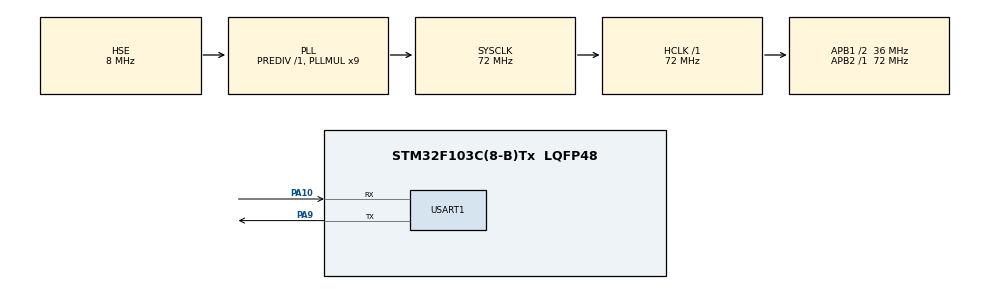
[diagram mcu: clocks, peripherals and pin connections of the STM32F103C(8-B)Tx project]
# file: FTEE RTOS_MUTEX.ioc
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FREERTOS.Mutexes01=myMutex01,Dynamic,NULL,Available
FREERTOS.Tasks01=defaultTask,24,128,StartDefaultTask,Default,NULL,Dynamic,NULL,NULL;TASK1,24,128,TASK_1,Default,NULL,Dynamic,NULL,NULL;TASK2,24,128,TASK_2,Default,NULL,Dynamic,NULL,NULL;TASK3,24,128,TASK_3,Default,NULL,Dynamic,NULL,NULL
Mcu.Family=STM32F1
Mcu.Name=STM32F103C(8-B)Tx
Mcu.Package=LQFP48
NVIC.PriorityGroup=NVIC_PRIORITYGROUP_4
NVIC.TIM1_UP_IRQn=true\:15\:0\:false\:false\:true\:false\:false\:true\:true
NVIC.TimeBase=TIM1_UP_IRQn
NVIC.TimeBaseIP=TIM1
PA10.Mode=Asynchronous
PA10.Signal=USART1_RX
PA9.Mode=Asynchronous
PA9.Signal=USART1_TX
PD0-OSC_IN.Mode=HSE-External-Oscillator
PD0-OSC_IN.Signal=RCC_OSC_IN
PD1-OSC_OUT.Mode=HSE-External-Oscillator
PD1-OSC_OUT.Signal=RCC_OSC_OUT
ProjectManager.HeapSize=0x200
ProjectManager.StackSize=0x400
ProjectManager.TargetToolchain=STM32CubeIDE
RCC.AHBFreq_Value=72000000
RCC.APB1CLKDivider=RCC_HCLK_DIV2
RCC.APB1Freq_Value=36000000
RCC.APB1TimFreq_Value=72000000
RCC.APB2Freq_Value=72000000
RCC.APB2TimFreq_Value=72000000
RCC.HCLKFreq_Value=72000000
RCC.PLLMUL=RCC_PLL_MUL9
RCC.PLLSourceVirtual=RCC_PLLSOURCE_HSE
RCC.SYSCLKFreq_VALUE=72000000
RCC.SYSCLKSource=RCC_SYSCLKSOURCE_PLLCLK
RCC.USBFreq_Value=72000000
USART1.VirtualMode=VM_ASYNC
VP_FREERTOS_VS_CMSIS_V2.Mode=CMSIS_V2
VP_SYS_VS_ND.Mode=No_Debug
VP_SYS_VS_tim1.Mode=TIM1
board=custom

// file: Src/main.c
/* USER CODE BEGIN Header */
/**
  ******************************************************************************
  * @file           : main.c
  * @brief          : Main program body
  ******************************************************************************
  * @attention
  *
  * Copyright (c) 2026 STMicroelectronics.
  * All rights reserved.
  *
  * This software is licensed under terms that can be found in the LICENSE file
  * in the root directory of this software component.
  * If no LICENSE file comes with this software, it is provided AS-IS.
  *
  ******************************************************************************
  */
/* USER CODE END Header */
#include "main.h"
#include "cmsis_os.h"

UART_HandleTypeDef huart1;

/* Definitions for defaultTask */
osThreadId_t defaultTaskHandle;
const osThreadAttr_t defaultTask_attributes = {
  .name = "defaultTask",
  .stack_size = 128 * 4,
  .priority = (osPriority_t) osPriorityNormal,
};
/* Definitions for TASK1 */
osThreadId_t TASK1Handle;
const osThreadAttr_t TASK1_attributes = {
  .name = "TASK1",
  .stack_size = 128 * 4,
  .priority = (osPriority_t) osPriorityNormal,
};
/* Definitions for TASK2 */
osThreadId_t TASK2Handle;
const osThreadAttr_t TASK2_attributes = {
  .name = "TASK2",
  .stack_size = 128 * 4,
  .priority = (osPriority_t) osPriorityNormal,
};
/* Definitions for TASK3 */
osThreadId_t TASK3Handle;
const osThreadAttr_t TASK3_attributes = {
  .name = "TASK3",
  .stack_size = 128 * 4,
  .priority = (osPriority_t) osPriorityNormal,
};
/* Definitions for myMutex01 */
osMutexId_t myMutex01Handle;
const osMutexAttr_t myMutex01_attributes = {
  .name = "myMutex01"
};

void SystemClock_Config(void);
static void MX_GPIO_Init(void);
static void MX_USART1_UART_Init(void);
void StartDefaultTask(void *argument);
void TASK_1(void *argument);
void TASK_2(void *argument);
void TASK_3(void *argument);

int main(void)
{

  HAL_Init();

  SystemClock_Config();

  MX_GPIO_Init();
  MX_USART1_UART_Init();

  osKernelInitialize();

  myMutex01Handle = osMutexNew(&myMutex01_attributes);

  defaultTaskHandle = osThreadNew(StartDefaultTask, NULL, &defaultTask_attributes);
  TASK1Handle       = osThreadNew(TASK_1, NULL, &TASK1_attributes);
  TASK2Handle       = osThreadNew(TASK_2, NULL, &TASK2_attributes);
  TASK3Handle       = osThreadNew(TASK_3, NULL, &TASK3_attributes);

  osKernelStart();

  while (1)
  {

  }
}

void SystemClock_Config(void)
{
  RCC_OscInitTypeDef RCC_OscInitStruct = {0};
  RCC_ClkInitTypeDef RCC_ClkInitStruct = {0};

  RCC_OscInitStruct.OscillatorType = RCC_OSCILLATORTYPE_HSE;
  RCC_OscInitStruct.HSEState = RCC_HSE_ON;
  RCC_OscInitStruct.HSEPredivValue = RCC_HSE_PREDIV_DIV1;
  RCC_OscInitStruct.HSIState = RCC_HSI_ON;
  RCC_OscInitStruct.PLL.PLLState = RCC_PLL_ON;
  RCC_OscInitStruct.PLL.PLLSource = RCC_PLLSOURCE_HSE;
  RCC_OscInitStruct.PLL.PLLMUL = RCC_PLL_MUL9;
  if (HAL_RCC_OscConfig(&RCC_OscInitStruct) != HAL_OK) Error_Handler();

  RCC_ClkInitStruct.ClockType = RCC_CLOCKTYPE_HCLK|RCC_CLOCKTYPE_SYSCLK
                              |RCC_CLOCKTYPE_PCLK1|RCC_CLOCKTYPE_PCLK2;
  RCC_ClkInitStruct.SYSCLKSource = RCC_SYSCLKSOURCE_PLLCLK;
  RCC_ClkInitStruct.AHBCLKDivider = RCC_SYSCLK_DIV1;
  RCC_ClkInitStruct.APB1CLKDivider = RCC_HCLK_DIV2;
  RCC_ClkInitStruct.APB2CLKDivider = RCC_HCLK_DIV1;
  if (HAL_RCC_ClockConfig(&RCC_ClkInitStruct, FLASH_LATENCY_2) != HAL_OK) Error_Handler();
}

static void MX_USART1_UART_Init(void)
{
  huart1.Instance = USART1;
  huart1.Init.BaudRate = 115200;
  huart1.Init.WordLength = UART_WORDLENGTH_8B;
  huart1.Init.StopBits = UART_STOPBITS_1;
  huart1.Init.Parity = UART_PARITY_NONE;
  huart1.Init.Mode = UART_MODE_TX_RX;
  huart1.Init.HwFlowCtl = UART_HWCONTROL_NONE;
  huart1.Init.OverSampling = UART_OVERSAMPLING_16;
  if (HAL_UART_Init(&huart1) != HAL_OK) Error_Handler();
}

static void MX_GPIO_Init(void)
{
  __HAL_RCC_GPIOD_CLK_ENABLE();
  __HAL_RCC_GPIOA_CLK_ENABLE();
}

void StartDefaultTask(void *argument)
{
  for(;;)
  {
    osDelay(1);
  }
}

/* USER CODE END Header_TASK_1 */
void TASK_1(void *argument)
{
  /* USER CODE BEGIN TASK_1 */
  for(;;)
  {
	  osMutexAcquire(myMutex01Handle, osWaitForever);
	  HAL_UART_Transmit(&huart1, (uint8_t*)"AM ", 3, 100);
	  osDelay(5);
	  HAL_UART_Transmit(&huart1, (uint8_t*)"SALAHALDEN\r\n", 12, 100);
	  osMutexRelease(myMutex01Handle);
	  osDelay(500);
  }
  /* USER CODE END TASK_1 */
}

void TASK_2(void *argument)
{
  /* USER CODE BEGIN TASK_2 */
  for(;;)
  {
	  osMutexAcquire(myMutex01Handle, osWaitForever);
	  HAL_UART_Transmit(&huart1, (uint8_t*)"HEL", 3, 100);
	  osDelay(5);
	  HAL_UART_Transmit(&huart1, (uint8_t*)"LO!\r\n", 5, 100);
	  osMutexRelease(myMutex01Handle);
	  osDelay(500);
  }
  /* USER CODE END TASK_2 */
}

void TASK_3(void *argument)
{
  /* USER CODE BEGIN TASK_3 */
  for(;;)
  {
	  osMutexAcquire(myMutex01Handle, osWaitForever);
	  HAL_UART_Transmit(&huart1, (uint8_t*)"DO", 2, 100);
	  osDelay(5);
	  HAL_UART_Transmit(&huart1, (uint8_t*)"NE\r\n", 4, 100);
	  osMutexRelease(myMutex01Handle);
	  osDelay(500);
  }
  /* USER CODE END TASK_3 */
}

void HAL_TIM_PeriodElapsedCallback(TIM_HandleTypeDef *htim)
{
  if (htim->Instance == TIM1)
  {
    HAL_IncTick();
  }
}

void Error_Handler(void)
{
  __disable_irq();
  while (1)
  {
  }
}
